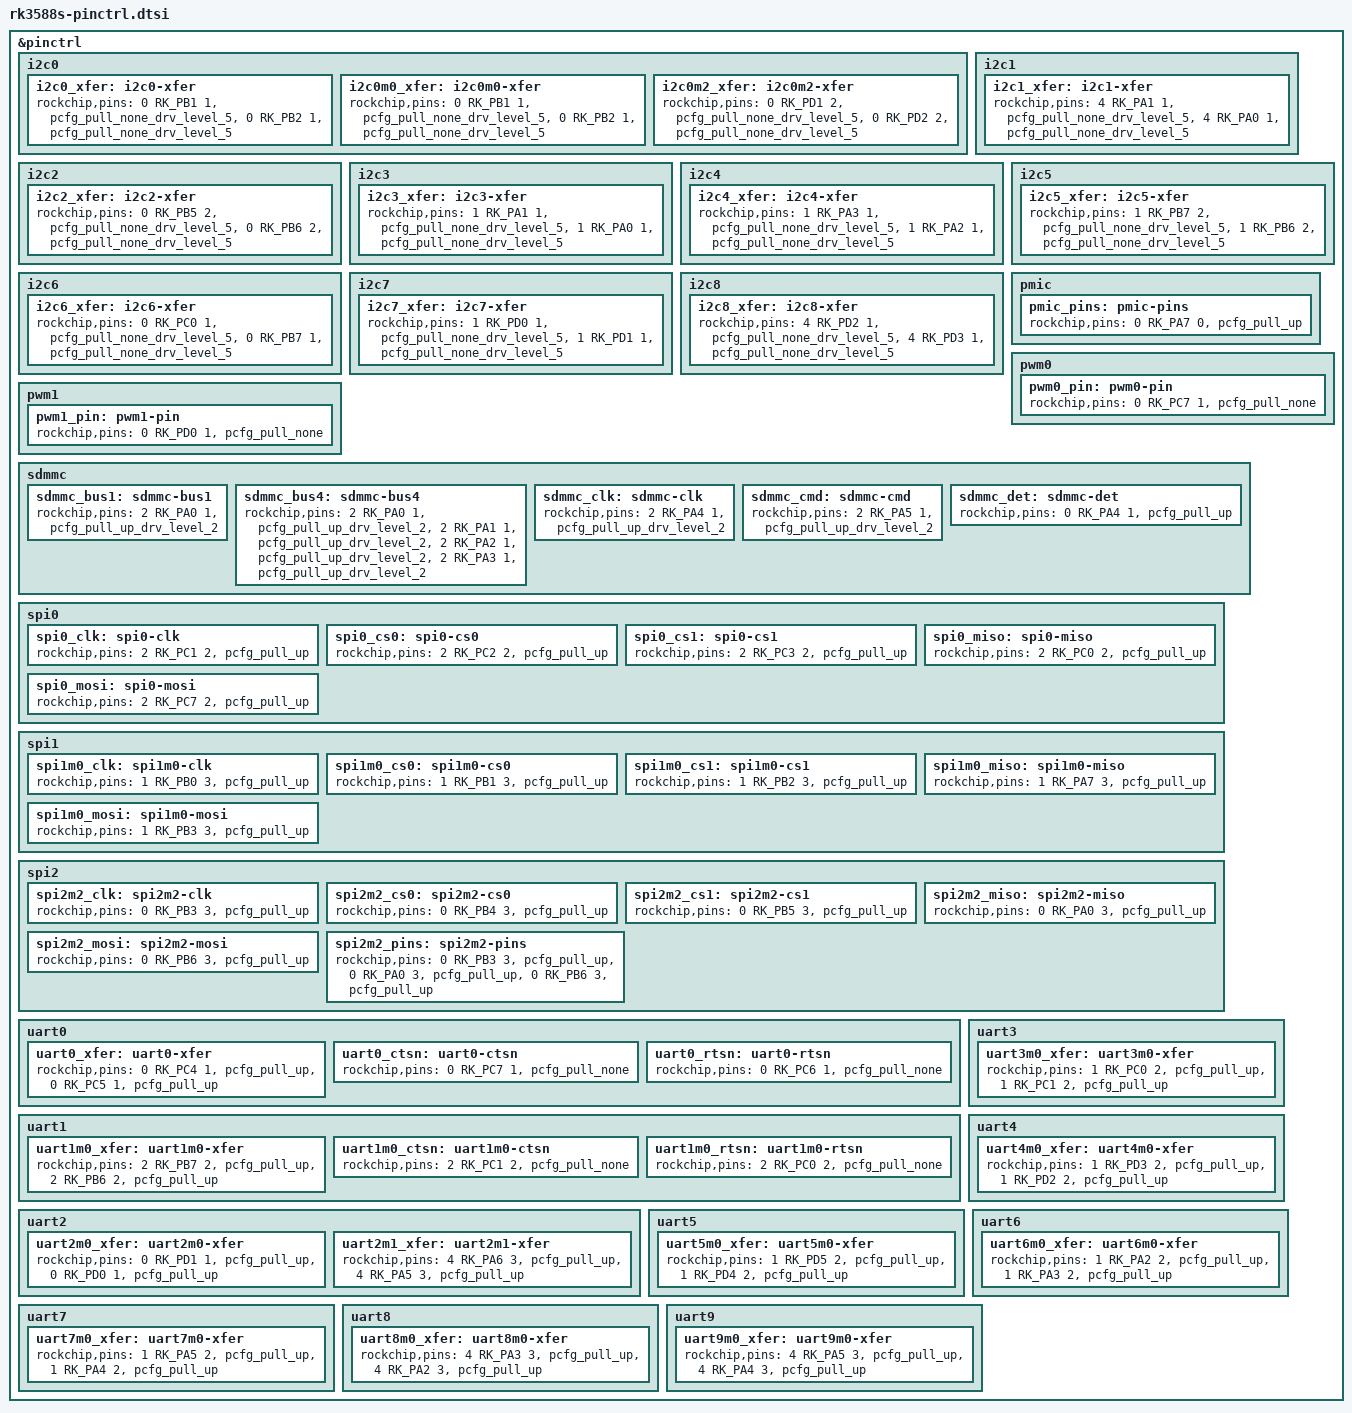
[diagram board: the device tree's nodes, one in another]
// SPDX-License-Identifier: (GPL-2.0+ OR MIT)
/*
 * Copyright (c) 2021 Rockchip Electronics Co., Ltd.
 */

&pinctrl {
	i2c0 {
		/omit-if-no-ref/
		i2c0_xfer: i2c0-xfer {
			rockchip,pins =
				/* i2c0_scl */
				<0 RK_PB1 1 &pcfg_pull_none_drv_level_5>,
				/* i2c0_sda */
				<0 RK_PB2 1 &pcfg_pull_none_drv_level_5>;
		};

		/omit-if-no-ref/
		i2c0m0_xfer: i2c0m0-xfer {
			rockchip,pins =
				/* i2c0_scl_m0 */
				<0 RK_PB1 1 &pcfg_pull_none_drv_level_5>,
				/* i2c0_sda_m0 */
				<0 RK_PB2 1 &pcfg_pull_none_drv_level_5>;
		};

		/omit-if-no-ref/
		i2c0m2_xfer: i2c0m2-xfer {
			rockchip,pins =
				/* i2c0_scl_m2 */
				<0 RK_PD1 2 &pcfg_pull_none_drv_level_5>,
				/* i2c0_sda_m2 */
				<0 RK_PD2 2 &pcfg_pull_none_drv_level_5>;
		};
	};

	i2c1 {
		/omit-if-no-ref/
		i2c1_xfer: i2c1-xfer {
			rockchip,pins =
				/* i2c1_scl */
				<4 RK_PA1 1 &pcfg_pull_none_drv_level_5>,
				/* i2c1_sda */
				<4 RK_PA0 1 &pcfg_pull_none_drv_level_5>;
		};
	};

	i2c2 {
		/omit-if-no-ref/
		i2c2_xfer: i2c2-xfer {
			rockchip,pins =
				/* i2c2_scl */
				<0 RK_PB5 2 &pcfg_pull_none_drv_level_5>,
				/* i2c2_sda */
				<0 RK_PB6 2 &pcfg_pull_none_drv_level_5>;
		};
	};

	i2c3 {
		/omit-if-no-ref/
		i2c3_xfer: i2c3-xfer {
			rockchip,pins =
				/* i2c3_scl */
				<1 RK_PA1 1 &pcfg_pull_none_drv_level_5>,
				/* i2c3_sda */
				<1 RK_PA0 1 &pcfg_pull_none_drv_level_5>;
		};
	};

	i2c4 {
		/omit-if-no-ref/
		i2c4_xfer: i2c4-xfer {
			rockchip,pins =
				/* i2c4_scl */
				<1 RK_PA3 1 &pcfg_pull_none_drv_level_5>,
				/* i2c4_sda */
				<1 RK_PA2 1 &pcfg_pull_none_drv_level_5>;
		};
	};

	i2c5 {
		/omit-if-no-ref/
		i2c5_xfer: i2c5-xfer {
			rockchip,pins =
				/* i2c5_scl */
				<1 RK_PB7 2 &pcfg_pull_none_drv_level_5>,
				/* i2c5_sda */
				<1 RK_PB6 2 &pcfg_pull_none_drv_level_5>;
		};
	};

	i2c6 {
		/omit-if-no-ref/
		i2c6_xfer: i2c6-xfer {
			rockchip,pins =
				/* i2c6_scl */
				<0 RK_PC0 1 &pcfg_pull_none_drv_level_5>,
				/* i2c6_sda */
				<0 RK_PB7 1 &pcfg_pull_none_drv_level_5>;
		};
	};

	i2c7 {
		/omit-if-no-ref/
		i2c7_xfer: i2c7-xfer {
			rockchip,pins =
				/* i2c7_scl */
				<1 RK_PD0 1 &pcfg_pull_none_drv_level_5>,
				/* i2c7_sda */
				<1 RK_PD1 1 &pcfg_pull_none_drv_level_5>;
		};
	};

	i2c8 {
		/omit-if-no-ref/
		i2c8_xfer: i2c8-xfer {
			rockchip,pins =
				/* i2c8_scl */
				<4 RK_PD2 1 &pcfg_pull_none_drv_level_5>,
				/* i2c8_sda */
				<4 RK_PD3 1 &pcfg_pull_none_drv_level_5>;
		};
	};

	pmic {
		/omit-if-no-ref/
		pmic_pins: pmic-pins {
			rockchip,pins =
				/* pmic_int_l */
				<0 RK_PA7 0 &pcfg_pull_up>;
		};
	};

	pwm0 {
		/omit-if-no-ref/
		pwm0_pin: pwm0-pin {
			rockchip,pins =
				/* pwm0_out */
				<0 RK_PC7 1 &pcfg_pull_none>;
		};
	};

	pwm1 {
		/omit-if-no-ref/
		pwm1_pin: pwm1-pin {
			rockchip,pins =
				/* pwm1_out */
				<0 RK_PD0 1 &pcfg_pull_none>;
		};
	};

	sdmmc {
		/omit-if-no-ref/
		sdmmc_bus1: sdmmc-bus1 {
			rockchip,pins =
				/* sdmmc_d0 */
				<2 RK_PA0 1 &pcfg_pull_up_drv_level_2>;
		};

		/omit-if-no-ref/
		sdmmc_bus4: sdmmc-bus4 {
			rockchip,pins =
				/* sdmmc_d0 */
				<2 RK_PA0 1 &pcfg_pull_up_drv_level_2>,
				/* sdmmc_d1 */
				<2 RK_PA1 1 &pcfg_pull_up_drv_level_2>,
				/* sdmmc_d2 */
				<2 RK_PA2 1 &pcfg_pull_up_drv_level_2>,
				/* sdmmc_d3 */
				<2 RK_PA3 1 &pcfg_pull_up_drv_level_2>;
		};

		/omit-if-no-ref/
		sdmmc_clk: sdmmc-clk {
			rockchip,pins =
				/* sdmmc_clk */
				<2 RK_PA4 1 &pcfg_pull_up_drv_level_2>;
		};

		/omit-if-no-ref/
		sdmmc_cmd: sdmmc-cmd {
			rockchip,pins =
				/* sdmmc_cmd */
				<2 RK_PA5 1 &pcfg_pull_up_drv_level_2>;
		};

		/omit-if-no-ref/
		sdmmc_det: sdmmc-det {
			rockchip,pins =
				/* sdmmc_det */
				<0 RK_PA4 1 &pcfg_pull_up>;
		};
	};

	spi0 {
		/omit-if-no-ref/
		spi0_clk: spi0-clk {
			rockchip,pins =
				/* spi0_clk */
				<2 RK_PC1 2 &pcfg_pull_up>;
		};

		/omit-if-no-ref/
		spi0_cs0: spi0-cs0 {
			rockchip,pins =
				/* spi0_cs0 */
				<2 RK_PC2 2 &pcfg_pull_up>;
		};

		/omit-if-no-ref/
		spi0_cs1: spi0-cs1 {
			rockchip,pins =
				/* spi0_cs1 */
				<2 RK_PC3 2 &pcfg_pull_up>;
		};

		/omit-if-no-ref/
		spi0_miso: spi0-miso {
			rockchip,pins =
				/* spi0_miso */
				<2 RK_PC0 2 &pcfg_pull_up>;
		};

		/omit-if-no-ref/
		spi0_mosi: spi0-mosi {
			rockchip,pins =
				/* spi0_mosi */
				<2 RK_PC7 2 &pcfg_pull_up>;
		};
	};

	spi1 {
		/omit-if-no-ref/
		spi1m0_clk: spi1m0-clk {
			rockchip,pins =
				/* spi1_clk_m0 */
				<1 RK_PB0 3 &pcfg_pull_up>;
		};

		/omit-if-no-ref/
		spi1m0_cs0: spi1m0-cs0 {
			rockchip,pins =
				/* spi1_cs0_m0 */
				<1 RK_PB1 3 &pcfg_pull_up>;
		};

		/omit-if-no-ref/
		spi1m0_cs1: spi1m0-cs1 {
			rockchip,pins =
				/* spi1_cs1_m0 */
				<1 RK_PB2 3 &pcfg_pull_up>;
		};

		/omit-if-no-ref/
		spi1m0_miso: spi1m0-miso {
			rockchip,pins =
				/* spi1_miso_m0 */
				<1 RK_PA7 3 &pcfg_pull_up>;
		};

		/omit-if-no-ref/
		spi1m0_mosi: spi1m0-mosi {
			rockchip,pins =
				/* spi1_mosi_m0 */
				<1 RK_PB3 3 &pcfg_pull_up>;
		};
	};

	spi2 {
		/omit-if-no-ref/
		spi2m2_clk: spi2m2-clk {
			rockchip,pins =
				/* spi2_clk_m2 */
				<0 RK_PB3 3 &pcfg_pull_up>;
		};

		/omit-if-no-ref/
		spi2m2_cs0: spi2m2-cs0 {
			rockchip,pins =
				/* spi2_cs0_m2 */
				<0 RK_PB4 3 &pcfg_pull_up>;
		};

		/omit-if-no-ref/
		spi2m2_cs1: spi2m2-cs1 {
			rockchip,pins =
				/* spi2_cs1_m2 */
				<0 RK_PB5 3 &pcfg_pull_up>;
		};

		/omit-if-no-ref/
		spi2m2_miso: spi2m2-miso {
			rockchip,pins =
				/* spi2_miso_m2 */
				<0 RK_PA0 3 &pcfg_pull_up>;
		};

		/omit-if-no-ref/
		spi2m2_mosi: spi2m2-mosi {
			rockchip,pins =
				/* spi2_mosi_m2 */
				<0 RK_PB6 3 &pcfg_pull_up>;
		};

		/omit-if-no-ref/
		spi2m2_pins: spi2m2-pins {
			rockchip,pins =
				/* spi2_clk_m2 */
				<0 RK_PB3 3 &pcfg_pull_up>,
				/* spi2_miso_m2 */
				<0 RK_PA0 3 &pcfg_pull_up>,
				/* spi2_mosi_m2 */
				<0 RK_PB6 3 &pcfg_pull_up>;
		};
	};

	uart0 {
		/omit-if-no-ref/
		uart0_xfer: uart0-xfer {
			rockchip,pins =
				/* uart0_rx */
				<0 RK_PC4 1 &pcfg_pull_up>,
				/* uart0_tx */
				<0 RK_PC5 1 &pcfg_pull_up>;
		};

		/omit-if-no-ref/
		uart0_ctsn: uart0-ctsn {
			rockchip,pins =
				/* uart0_ctsn */
				<0 RK_PC7 1 &pcfg_pull_none>;
		};

		/omit-if-no-ref/
		uart0_rtsn: uart0-rtsn {
			rockchip,pins =
				/* uart0_rtsn */
				<0 RK_PC6 1 &pcfg_pull_none>;
		};
	};

	uart1 {
		/omit-if-no-ref/
		uart1m0_xfer: uart1m0-xfer {
			rockchip,pins =
				/* uart1_rx_m0 */
				<2 RK_PB7 2 &pcfg_pull_up>,
				/* uart1_tx_m0 */
				<2 RK_PB6 2 &pcfg_pull_up>;
		};

		/omit-if-no-ref/
		uart1m0_ctsn: uart1m0-ctsn {
			rockchip,pins =
				/* uart1_ctsn_m0 */
				<2 RK_PC1 2 &pcfg_pull_none>;
		};

		/omit-if-no-ref/
		uart1m0_rtsn: uart1m0-rtsn {
			rockchip,pins =
				/* uart1_rtsn_m0 */
				<2 RK_PC0 2 &pcfg_pull_none>;
		};
	};

	uart2 {
		/omit-if-no-ref/
		uart2m0_xfer: uart2m0-xfer {
			rockchip,pins =
				/* uart2_rx_m0 */
				<0 RK_PD1 1 &pcfg_pull_up>,
				/* uart2_tx_m0 */
				<0 RK_PD0 1 &pcfg_pull_up>;
		};

		/omit-if-no-ref/
		uart2m1_xfer: uart2m1-xfer {
			rockchip,pins =
				/* uart2_rx_m1 */
				<4 RK_PA6 3 &pcfg_pull_up>,
				/* uart2_tx_m1 */
				<4 RK_PA5 3 &pcfg_pull_up>;
		};
	};

	uart3 {
		/omit-if-no-ref/
		uart3m0_xfer: uart3m0-xfer {
			rockchip,pins =
				/* uart3_rx_m0 */
				<1 RK_PC0 2 &pcfg_pull_up>,
				/* uart3_tx_m0 */
				<1 RK_PC1 2 &pcfg_pull_up>;
		};
	};

	uart4 {
		/omit-if-no-ref/
		uart4m0_xfer: uart4m0-xfer {
			rockchip,pins =
				/* uart4_rx_m0 */
				<1 RK_PD3 2 &pcfg_pull_up>,
				/* uart4_tx_m0 */
				<1 RK_PD2 2 &pcfg_pull_up>;
		};
	};

	uart5 {
		/omit-if-no-ref/
		uart5m0_xfer: uart5m0-xfer {
			rockchip,pins =
				/* uart5_rx_m0 */
				<1 RK_PD5 2 &pcfg_pull_up>,
				/* uart5_tx_m0 */
				<1 RK_PD4 2 &pcfg_pull_up>;
		};
	};

	uart6 {
		/omit-if-no-ref/
		uart6m0_xfer: uart6m0-xfer {
			rockchip,pins =
				/* uart6_rx_m0 */
				<1 RK_PA2 2 &pcfg_pull_up>,
				/* uart6_tx_m0 */
				<1 RK_PA3 2 &pcfg_pull_up>;
		};
	};

	uart7 {
		/omit-if-no-ref/
		uart7m0_xfer: uart7m0-xfer {
			rockchip,pins =
				/* uart7_rx_m0 */
				<1 RK_PA5 2 &pcfg_pull_up>,
				/* uart7_tx_m0 */
				<1 RK_PA4 2 &pcfg_pull_up>;
		};
	};

	uart8 {
		/omit-if-no-ref/
		uart8m0_xfer: uart8m0-xfer {
			rockchip,pins =
				/* uart8_rx_m0 */
				<4 RK_PA3 3 &pcfg_pull_up>,
				/* uart8_tx_m0 */
				<4 RK_PA2 3 &pcfg_pull_up>;
		};
	};

	uart9 {
		/omit-if-no-ref/
		uart9m0_xfer: uart9m0-xfer {
			rockchip,pins =
				/* uart9_rx_m0 */
				<4 RK_PA5 3 &pcfg_pull_up>,
				/* uart9_tx_m0 */
				<4 RK_PA4 3 &pcfg_pull_up>;
		};
	};
};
